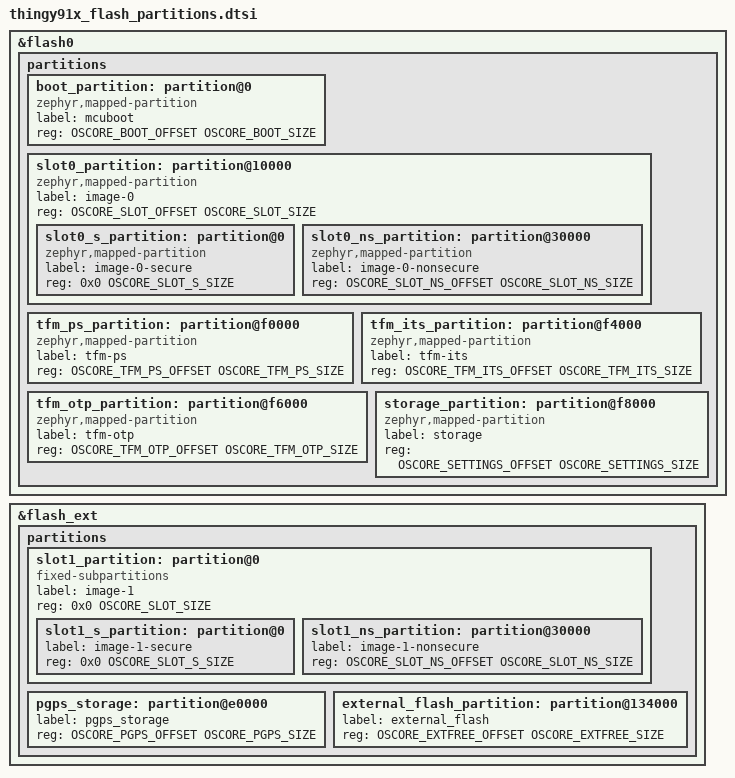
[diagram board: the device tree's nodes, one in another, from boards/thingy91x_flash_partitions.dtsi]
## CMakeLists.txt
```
# SPDX-License-Identifier: Apache-2.0
#
# Minimal OSCORE cloud sample for the nRF9151 DK. The oscore_cloud library is
# pulled in as a Zephyr module by the west manifest (west.yml), so it is built
# and linked automatically when CONFIG_OSCORE_CLOUD=y; this app only compiles
# its own main().

cmake_minimum_required(VERSION 3.20.0)

find_package(Zephyr REQUIRED HINTS $ENV{ZEPHYR_BASE})
project(oscore_nrf9151_app)

target_sources(app PRIVATE
	src/main.c
	src/network.c
)

target_sources_ifdef(CONFIG_LOCATION app PRIVATE
	src/location.c
	src/soak.c
)
```

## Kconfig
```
# SPDX-License-Identifier: Apache-2.0

mainmenu "OSCORE nRF9151 sample"

config APP_SAMPLE_INTERVAL_SECONDS
	int "Telemetry send interval (seconds)"
	default 600
	help
	  How long the main loop sleeps between telemetry check-ins once the
	  OSCORE cloud connection is established.

config APP_VERSION
	string "Reported firmware version string"
	default "1.0.0-oscore-sample"
	help
	  Value reported to the cloud in telemetry well-known key 2 (fw version).
	  Must be shorter than 24 bytes.

config APP_LINK_TIMEOUT_SECONDS
	int "LTE link-up wait timeout (seconds)"
	default 180
	help
	  How long to wait for the modem to register on the LTE network, both at
	  boot and after a link drop, before the recovery ladder escalates to the
	  next stage. The modem keeps searching in the background regardless.

config APP_MODEM_REINIT_AFTER_FAILURES
	int "Consecutive failures before reinitialising the modem"
	default 4
	help
	  Number of consecutive link-recovery attempts after which the recovery
	  ladder reaches its heaviest local step: a full modem-library
	  shutdown/reinit. Below this threshold it waits for auto re-registration
	  and, from the second failure, forces an LTE offline/normal re-attach.

config APP_AGNSS_SINGLE_SHOT_MAX_SV
	int "Single-shot A-GNSS satellite cap"
	depends on LOCATION && OSCORE_CLOUD_AGNSS
	default 9
	help
	  Number of satellites requested for a single-shot GNSS fix ("loc single"):
	  the server keeps only satellites visible now (>=10 deg elevation), picks
	  the strongest one per azimuth sector, and caps to this many for a small
	  assistance payload. 9 gives an extra strong SV of acquisition margin over
	  the 8-SV minimum while staying well under 1 kB with compact encoding. 0
	  leaves it uncapped.

source "Kconfig.zephyr"
```

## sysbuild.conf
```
# SPDX-License-Identifier: Apache-2.0
#
# Build MCUboot as the bootloader at flash 0x0. On the nRF9151 DK the board's
# flash layout reserves 0x0..0x10000 for the bootloader and links TF-M / the
# application AFTER it, so without MCUboot nothing valid sits at the reset
# address: the device boots into empty flash, faults, and produces no UART
# output. MCUboot boots from 0x0 and chainloads the TF-M secure image.
SB_CONFIG_BOOTLOADER_MCUBOOT=y

# Drop the immutable bootloader (b0) + updatable-MCUboot (s0/s1) chain that the
# Thingy:91 X enables by default for its factory partition layout. This app
# replaces that layout with the nRF9151 DK's -- a single first-stage MCUboot in
# boot_partition -- so that both boards have byte-identical internal flash; see
# boards/thingy91x_flash_partitions.dtsi. A second-stage MCUboot would also
# refuse to build here, since it requires zephyr,code-partition to be s0 or s1.
# No-op on the nRF9151 DK, which never enables secure boot.
SB_CONFIG_SECURE_BOOT_APPCORE=n
```

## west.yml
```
# SPDX-License-Identifier: Apache-2.0
#
# West T2 (star) manifest for the OSCORE nRF9151 sample.
#
# It imports sdk-nrf (which in turn imports Zephyr and all the usual modules),
# then adds two same-named / extra project entries that the top manifest wins
# over the imported ones:
#
#   * uoscore-uedhoc -> the joncloud-dev fork carrying the opaque PSA-key
#     changes required by the oscore_cloud library. A project with this name is
#     already pulled in by the sdk-nrf import; re-declaring it here at the top
#     level overrides that pin with our fork + branch.
#   * oscore_cloud   -> the reusable OSCORE cloud client module.
#
# To build against this manifest, clone this repo into an EMPTY workspace
# directory and run `west init -l . && west update` from there (this pulls the
# full NCS tree as siblings). For day-to-day iteration you can instead build
# inside an existing NCS workspace (see README).

manifest:
  version: "0.13"

  remotes:
    - name: ncs
      url-base: https://github.com/nrfconnect
    - name: joncloud-dev
      url-base: https://github.com/joncloud-dev

  projects:
    - name: sdk-nrf
      remote: ncs
      repo-path: sdk-nrf
      revision: 9f9725b23bc137e1e047c6a33773893b2c25ce0f  # NCS main (v3.4.99), 2026-11-03
      import: true

    # Overrides the uoscore-uedhoc pin imported via sdk-nrf with the fork that
    # provides opaque PSA master keys (branch oscore-opaque-psa-keys).
    - name: uoscore-uedhoc
      remote: joncloud-dev
      repo-path: uoscore-uedhoc
      revision: oscore-opaque-psa-keys
      path: modules/lib/uoscore-uedhoc

    # The reusable OSCORE cloud client library (standalone Zephyr module).
    - name: oscore_cloud
      remote: joncloud-dev
      repo-path: oscore_cloud
      revision: main
      path: modules/lib/oscore_cloud

  self:
    path: oscore_nrf9151_app
```

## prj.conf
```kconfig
# SPDX-License-Identifier: Apache-2.0
#
# Minimal configuration for the OSCORE cloud sample on nRF9151. Distilled from
# the Asset-Tracker-Template prj.conf: keeps only what the oscore_cloud library
# and its plain main()-loop session helper need (no zbus / SMF / storage / FOTA /
# location / diagnostics).

CONFIG_NCS_SAMPLES_DEFAULTS=y
# The diagnostics module (below) installs its own k_sys_fatal_error_handler to
# capture a crash snapshot before rebooting, so Zephyr's default reset-on-fatal
# handler must be disabled to keep a single definition of the symbol.
CONFIG_RESET_ON_FATAL_ERROR=n

# This sample drives OSCORE directly from the main thread, so main needs the
# headroom ATT gives its dedicated 14 KB cloud thread: with VLAs off, uoscore
# stages its plaintext[]/ciphertext[] buffers (OSCORE_MAX_PLAINTEXT_LEN=1536 +
# tag) plus the CoAP/telemetry frame on the caller's stack. 8 KB overflows on
# the first telemetry protect; 16 KB matches the known-good nrf9151_client.
CONFIG_MAIN_STACK_SIZE=16384
CONFIG_HEAP_MEM_POOL_SIZE=12288
CONFIG_HEAP_MEM_POOL_IGNORE_MIN=y
# Deferred AT monitors heap-copy notifications in the IPC ISR; 1 KiB default
# exhausts after a registration/PDN notification burst (e.g. post-flight).
CONFIG_AT_MONITOR_HEAP_SIZE=6144
CONFIG_EXTRA_EXCEPTION_INFO=y

# ---------------------------------------------------------------------------
# TF-M full profile: PSA crypto service required by uoscore-uedhoc (opaque
# master-secret key lives in the TF-M secure domain).
# ---------------------------------------------------------------------------
CONFIG_TFM_PROFILE_TYPE_NOT_SET=y
CONFIG_PSA_CRYPTO_DRIVER_CC3XX=y
CONFIG_TFM_PSA_FRAMEWORK_HAS_MM_IOVEC=y
CONFIG_PSA_WANT_ALG_CTR_DRBG=y

# Put TF-M's secure log on UART0 and share that instance with the non-secure
# app so both TF-M and the application console/shell come out on the DK's VCOM.
# Without this, TF-M defaults to a separate secure UART (uart1) and the console
# ends up on a port you are not watching -> "no UART output".
CONFIG_TFM_SECURE_UART0=y
CONFIG_TFM_SECURE_UART_SHARE_INSTANCE=y

# ---------------------------------------------------------------------------
# Networking: modem-offloaded sockets on the nRF91 (no native IP stack).
# ---------------------------------------------------------------------------
CONFIG_NETWORKING=y
CONFIG_NET_SOCKETS=y
CONFIG_NET_NATIVE=n
CONFIG_NET_IPV4=y

CONFIG_NRF_MODEM_LIB=y
CONFIG_LTE_LINK_CONTROL=y
CONFIG_LTE_NETWORK_MODE_LTE_M_NBIOT_GPS=y

# LTE Link Control submodules used by the network module (src/network.c):
#  - PDN: the network module treats the default-PDN activate/deactivate events
#    as the authoritative link-up/down signal (an IP bearer is actually usable),
#    rather than raw registration status.
#  - MODEM_EVENTS: surfaces attach reset-loop and light/full search-done
#    notifications (enabled automatically by the lte_lc CFUN hook).
#  - PSM/eDRX: request power-saving parameters and forward the negotiated values
#    to the application as network events.
CONFIG_LTE_LC_PDN_MODULE=y
CONFIG_LTE_LC_MODEM_EVENTS_MODULE=y
CONFIG_LTE_LC_PSM_MODULE=y
CONFIG_LTE_PSM_REQ=y
CONFIG_LTE_LC_EDRX_MODULE=y
CONFIG_LTE_EDRX_REQ=y
CONFIG_LTE_PSM_REQ_RPTAU_SECONDS=7200
CONFIG_LTE_PSM_REQ_RAT_SECONDS=6
# Modem info: feeds the diagnostics vitals heartbeat (RSRP/SNR/temp/band, tx/rx
# airtime) and the one-shot device-info report (modem firmware, IMEI, ICCID).
CONFIG_MODEM_INFO=y
CONFIG_MODEM_INFO_ADD_NETWORK=y

# Wall-clock time (optional telemetry timestamp; the server also stamps).
CONFIG_DATE_TIME=y

# ---------------------------------------------------------------------------
# GNSS location + A-GNSS assistance over OSCORE.
#
# The Location library runs a GNSS-only search (src/location.c). A-GNSS
# assistance is fetched from the OSCORE cloud, not nRF Cloud. The Location
# library only *exposes* the external assistance-request event
# (LOCATION_EVT_GNSS_ASSISTANCE_REQUEST + event_data.agnss_request) when
# CONFIG_NRF_CLOUD_AGNSS is set, which in turn lives under CONFIG_NRF_CLOUD.
# We therefore enable the nRF Cloud *library* for the request plumbing only:
# with no transport (no NRF_CLOUD_MQTT/COAP) and CONFIG_LOCATION_SERVICE_EXTERNAL
# =y, no connection is made — the library hands the request to our handler,
# which fetches over OSCORE and injects via nrf_modem_gnss_agnss_write().
CONFIG_LOCATION=y
CONFIG_LOCATION_DATA_DETAILS=y
CONFIG_LOCATION_METHOD_GNSS=y
CONFIG_LOCATION_SERVICE_EXTERNAL=y
CONFIG_NRF_CLOUD=y
CONFIG_NRF_CLOUD_AGNSS=y
CONFIG_LOCATION_REQUEST_DEFAULT_GNSS_TIMEOUT=120000
CONFIG_LOCATION_REQUEST_DEFAULT_TIMEOUT=120000

# The Location library always builds scan_cellular.c, which requires an AT
# monitor heap large enough to hold neighbor-cell measurement notifications.
CONFIG_AT_MONITOR_HEAP_SIZE=1024

# oscore_cloud A-GNSS client (POST /a, Block2 CBOR -> nrf_modem_gnss_agnss_write).
CONFIG_OSCORE_CLOUD_AGNSS=y

# oscore_cloud predicted-GNSS (P-GPS) client (POST /p, Block2 CBOR -> flash
# window ring -> nrf_modem_gnss_agnss_write). Exposes the `pgps fetch` /
# `pgps fix` / `pgps store` shell commands.
CONFIG_OSCORE_CLOUD_PGPS=y
# Keep the downloaded windows in the pgps_storage partition on external flash
# (boards/nrf9151dk_nrf9151_ns.overlay), one 4 KiB slot per 4 h window. 84 slots
# is the full 14-day horizon the /p contract defines, and it survives reboots so
# the device can fix from stored predictions while completely offline -- which is
# what the `soak` bench test measures.
CONFIG_OSCORE_CLOUD_PGPS_STORE=y
CONFIG_OSCORE_CLOUD_PGPS_STORE_SLOTS=84
# Windows per POST /p. A whole horizon cannot arrive in one response (84 windows
# is ~97 kB against a 12 KiB accumulation buffer), so a long fetch is split into
# this many windows per request, one request per main-loop iteration.
CONFIG_OSCORE_CLOUD_PGPS_FETCH_BATCH=6

# ---------------------------------------------------------------------------
# OSCORE cloud transport.
# ---------------------------------------------------------------------------
CONFIG_COAP=y
CONFIG_UOSCORE=y
CONFIG_OSCORE_USE_EDHOC=n
CONFIG_ZCBOR=y
CONFIG_ZCBOR_CANONICAL=y
CONFIG_MBEDTLS=y
CONFIG_PSA_WANT_ALG_HMAC=y
CONFIG_PSA_WANT_ALG_SHA_256=y
CONFIG_PSA_WANT_KEY_TYPE_HMAC=y
CONFIG_PSA_WANT_ALG_CCM=y
CONFIG_PSA_WANT_KEY_TYPE_AES=y
#CONFIG_OSCORE_SERVER_IP="23.88.115.159"
CONFIG_OSCORE_SERVER_IP="34.148.113.218"

CONFIG_COAP_MAX_RETRANSMIT=3
CONFIG_COAP_INIT_ACK_TIMEOUT_MS=5000

# ---------------------------------------------------------------------------
# oscore_cloud library: enable the client and the framework-free session helper
# (connect / backoff / send_telemetry).
# ---------------------------------------------------------------------------
CONFIG_OSCORE_CLOUD=y
CONFIG_OSCORE_CLOUD_SESSION=y

# OSCORE FOTA of the application image (GET/POST /f + Block2 /f/i). The session
# helper drives the download when a telemetry response flags a pending job;
# main.c calls fota_client_boot_check() at boot to confirm the swapped image and
# report the result. The image streams into the MCUboot secondary slot on
# external flash; progress is persisted so an interrupted download resumes.
CONFIG_OSCORE_CLOUD_FOTA=y
CONFIG_DFU_TARGET=y
CONFIG_DFU_TARGET_MCUBOOT=y
CONFIG_DFU_TARGET_STREAM=y
CONFIG_DFU_TARGET_STREAM_SAVE_PROGRESS=y
CONFIG_STREAM_FLASH=y
CONFIG_IMG_MANAGER=y
CONFIG_MCUBOOT_IMG_MANAGER=y
CONFIG_IMG_ERASE_PROGRESSIVELY=y
CONFIG_DFU_TARGET_LOG_LEVEL_INF=y

# The network module (src/network.c) tracks the LTE link state with a kernel
# event object (k_event) so the main connect/send loop can block on, and react
# to, default-PDN activation/deactivation.
CONFIG_EVENTS=y

# ---------------------------------------------------------------------------
# Device observability (Memfault-style): reboot reasons (key 20), a health
# vitals heartbeat (key 21), minimal crash reports (key 22) and static device
# info (key 23), all folded into the ordinary telemetry uplink. The session
# helper attaches them automatically (OSCORE_CLOUD_DIAG_AUTO_ATTACH, default y);
# main.c only calls oscore_cloud_diag_init() once at boot. See OBSERVABILITY.md.
# ---------------------------------------------------------------------------
CONFIG_OSCORE_CLOUD_DIAG=y
CONFIG_OSCORE_CLOUD_DIAG_VITALS=y
CONFIG_OSCORE_CLOUD_DIAG_CRASH=y
CONFIG_OSCORE_CLOUD_DIAG_BREADCRUMBS=y
CONFIG_OSCORE_CLOUD_DIAG_BREADCRUMB_SIZE=1024
CONFIG_OSCORE_CLOUD_DIAG_BUILD_ID=y
CONFIG_OSCORE_CLOUD_DIAG_DEVICE_INFO=y
# Attach the vitals heartbeat on every telemetry send (raise to post fleet
# vitals at a lower cadence than telemetry while sharing the same packet).
CONFIG_OSCORE_CLOUD_DIAG_VITALS_INTERVAL=1

# Reset cause + planned reboot (selected by OSCORE_CLOUD_DIAG, listed for clarity).
CONFIG_HWINFO=y
CONFIG_REBOOT=y

# Vitals sources: heap/stack headroom and CPU busy percent. Modem signal quality
# and airtime vitals reuse CONFIG_MODEM_INFO / CONFIG_LTE_LINK_CONTROL above.
CONFIG_SYS_HEAP_RUNTIME_STATS=y
CONFIG_THREAD_MONITOR=y
CONFIG_THREAD_STACK_INFO=y
CONFIG_THREAD_RUNTIME_STATS=y

# Full coredump is off. It was originally disabled because the image did not fit
# the 256 KB application slot alongside the Location + nRF Cloud (A-GNSS request
# plumbing) + cJSON libraries. That constraint is gone -- moving the MCUboot
# secondary slot to external flash gave the application 704 KB (see
# boards/oscore_flash_layout.h) -- so this can be re-enabled now; it also needs a
# coredump_partition nodelabel, which neither board layout defines yet. The
# minimal inline crash report (diag key 22) covers the crash case meanwhile.
CONFIG_DEBUG_COREDUMP=n

# ---------------------------------------------------------------------------
# Persistent storage: the OSCORE Sender Sequence Number (replay counter) is
# saved to NVS so the server does not reject requests as replays after reboot.
# Uses the board's default `storage_partition` on internal flash.
# ---------------------------------------------------------------------------
CONFIG_FLASH=y
CONFIG_FLASH_MAP=y
CONFIG_NVS=y
CONFIG_SETTINGS=y
CONFIG_SETTINGS_NVS=y

# ---------------------------------------------------------------------------
# Shell: one-time bench provisioning via `oscore provision <secret> <salt>
# <sender_id> <recipient_id>` (registered by the oscore_cloud library).
# ---------------------------------------------------------------------------
CONFIG_UART_INTERRUPT_DRIVEN=y
CONFIG_SHELL=y
CONFIG_SHELL_STACK_SIZE=2560
CONFIG_SHELL_CMD_BUFF_SIZE=2048

# Floating point for telemetry values.
CONFIG_PICOLIBC=y
CONFIG_FPU=y

# Logging.
CONFIG_LOG=y
CONFIG_LOG_MODE_DEFERRED=y
CONFIG_LOG_BUFFER_SIZE=2048
# Needed to log the negotiated eDRX/PTW values (floats) from the network module.
CONFIG_CBPRINTF_FP_SUPPORT=y
# Keep the OSCORE cloud library at INF (default): DBG-level strings are rodata
# that no longer fits once the GNSS/location libraries are linked in.
CONFIG_LOCATION_LOG_LEVEL_DBG=y
```

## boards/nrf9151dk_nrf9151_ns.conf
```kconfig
# SPDX-License-Identifier: Apache-2.0
#
# Enable the DK's external SPI NOR flash (GD25WB256, 32 MiB on spi3 CS1). The
# node ships `status = "disabled"` in the board devicetree; the overlay enables
# it and carves out the pgps_storage partition that holds the predicted-GNSS
# window ring. There is no QSPI on the nRF9151, so this is a plain SPI NOR
# driver over SPIM.
CONFIG_SPI=y
CONFIG_SPI_NOR=y
CONFIG_SPI_NOR_SFDP_DEVICETREE=y
CONFIG_SPI_NOR_FLASH_LAYOUT_PAGE_SIZE=4096
```

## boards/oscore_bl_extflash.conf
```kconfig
# SPDX-License-Identifier: Apache-2.0
#
# MCUboot's secondary slot (slot1_partition) is on external SPI NOR on both
# boards, so the bootloader needs the driver to read and swap it. Keeping slot1
# internal instead would cost the application 448 KB of the 1 MiB part -- see
# boards/oscore_flash_layout.h.
CONFIG_SPI=y
CONFIG_SPI_NOR=y
CONFIG_SPI_NOR_SFDP_DEVICETREE=y
CONFIG_SPI_NOR_FLASH_LAYOUT_PAGE_SIZE=4096
```

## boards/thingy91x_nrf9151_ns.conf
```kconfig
# SPDX-License-Identifier: Apache-2.0
#
# The predicted-GNSS window ring lives in the pgps_storage partition on the
# on-board external SPI NOR flash (GD25LE255E, 32 MiB on spi3 CS0), so the
# application needs the SPI NOR driver. There is no QSPI on the nRF9151.
#
# Note that settings/NVS is on INTERNAL flash on this target (see
# thingy91x_flash_partitions.dtsi), so CONFIG_SPI_NRFX_RAM_BUFFER_SIZE does not
# need raising: nothing writes rodata-resident buffers over SPIM.
CONFIG_SPI=y
CONFIG_SPI_NOR=y
CONFIG_SPI_NOR_SFDP_DEVICETREE=y
CONFIG_SPI_NOR_FLASH_LAYOUT_PAGE_SIZE=4096

# This app replaces the factory b0 + s0/s1 chain with a single first-stage
# MCUboot (SB_CONFIG_SECURE_BOOT_APPCORE=n in sysbuild.conf), so the immutable
# bootloader is not present and the application must not build against its
# interface. The board's Kconfig.defconfig turns this on by default.
CONFIG_SECURE_BOOT=n
```

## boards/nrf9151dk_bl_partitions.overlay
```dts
/*
 * SPDX-License-Identifier: Apache-2.0
 *
 * Flash layout for the nrf9151dk MCUboot image, applied by sysbuild.cmake.
 *
 * MCUboot must see exactly the same partition bounds as the application: this
 * app grows slot0 and moves slot1 to external flash, and a bootloader that
 * disagreed would write its image trailer outside the slot. Board .overlay files
 * reach only the application image, hence this.
 */

#include "nrf9151dk_flash_partitions.dtsi"

/*
 * Link MCUboot into boot_partition.
 *
 * MCUboot's own boot/zephyr/app.overlay is what normally chooses this, but it is
 * only applied when Zephyr does not find a board-specific overlay in
 * boot/zephyr/boards/. MCUboot ships one for the Thingy:91 X
 * (thingy91x_nrf9151.overlay, which just raises the UART baud), so on that board
 * app.overlay is skipped and zephyr,code-partition stays &slot0_partition from
 * the board devicetree -- linking MCUboot on top of the application image and
 * leaving nothing at the reset vector. Set it explicitly here, for both boards,
 * so the layout does not depend on which overlays upstream happens to ship.
 */
/ {
	chosen {
		zephyr,code-partition = &boot_partition;
	};
};
```

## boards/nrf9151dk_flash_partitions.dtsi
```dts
/*
 * SPDX-License-Identifier: Apache-2.0
 *
 * nRF9151 DK flash layout. Shared by the application image and by MCUboot (see
 * sysbuild.cmake); both must agree, or MCUboot writes its image trailer outside
 * the slot. Addresses and sizes come from oscore_flash_layout.h, which documents
 * the layout and why it is what it is.
 *
 * The board's stock devicetree (zephyr/dts/vendor/nordic/nrf91xx_partition.dtsi)
 * already provides boot_partition, the TF-M storage areas and the settings
 * partition at the right addresses, so only the two image slots are rebuilt:
 * slot0 grows into the 448 KB that slot1 used to occupy, and slot1 moves to the
 * external SPI NOR chip.
 */

#include "oscore_flash_layout.h"

/delete-node/ &slot0_partition;
/delete-node/ &slot1_partition;

&flash0 {
	partitions {
		slot0_partition: partition@10000 {
			compatible = "zephyr,mapped-partition";
			label = "image-0";
			reg = <OSCORE_SLOT_OFFSET OSCORE_SLOT_SIZE>;
			ranges = <0x0 OSCORE_SLOT_OFFSET OSCORE_SLOT_SIZE>;
			#address-cells = <1>;
			#size-cells = <1>;

			slot0_s_partition: partition@0 {
				compatible = "zephyr,mapped-partition";
				label = "image-0-secure";
				reg = <0x0 OSCORE_SLOT_S_SIZE>;
			};

			slot0_ns_partition: partition@30000 {
				compatible = "zephyr,mapped-partition";
				label = "image-0-nonsecure";
				reg = <OSCORE_SLOT_NS_OFFSET OSCORE_SLOT_NS_SIZE>;
			};
		};
	};
};

/* The DK's 32 MiB GD25WB256 sits on spi3 CS1 and ships disabled; spi3 itself is
 * already enabled by the board. Enabled here rather than in the board .overlay
 * so MCUboot, which now reaches slot1 through it, gets it too. */
&gd25wb256 {
	status = "okay";

	partitions {
		compatible = "fixed-partitions";
		#address-cells = <1>;
		#size-cells = <1>;

		slot1_partition: partition@0 {
			compatible = "fixed-subpartitions";
			label = "image-1";
			/* MUST equal slot0_partition: MCUboot's swap refuses to run
			 * when the primary and secondary slots differ in size. */
			reg = <0x0 OSCORE_SLOT_SIZE>;
			ranges = <0x0 0x0 OSCORE_SLOT_SIZE>;
			#address-cells = <1>;
			#size-cells = <1>;

			slot1_s_partition: partition@0 {
				label = "image-1-secure";
				reg = <0x0 OSCORE_SLOT_S_SIZE>;
			};

			slot1_ns_partition: partition@30000 {
				label = "image-1-nonsecure";
				reg = <OSCORE_SLOT_NS_OFFSET OSCORE_SLOT_NS_SIZE>;
			};
		};

		pgps_storage: partition@e0000 {
			label = "pgps_storage";
			reg = <OSCORE_PGPS_OFFSET OSCORE_PGPS_SIZE>;
		};

		external_flash_partition: partition@134000 {
			label = "external_flash";
			reg = <OSCORE_EXTFREE_OFFSET OSCORE_EXTFREE_SIZE>;
		};
	};
};
```

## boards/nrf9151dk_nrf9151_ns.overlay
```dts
/*
 * SPDX-License-Identifier: Apache-2.0
 *
 * nRF9151 DK application image.
 *
 * The flash layout is shared with the MCUboot image (see sysbuild.cmake and
 * nrf9151dk_flash_partitions.dtsi). Two things it changes from the board default,
 * both explained in oscore_flash_layout.h: the secure/non-secure boundary inside
 * slot0 moves down so TF-M's full profile fits, and slot1 moves to the external
 * SPI NOR chip so the application gets 704 KB instead of 256 KB.
 *
 * The SRAM split is the board's stock 88 KB secure / 168 KB non-secure, which
 * this app already runs with.
 */

#include "nrf9151dk_flash_partitions.dtsi"
```

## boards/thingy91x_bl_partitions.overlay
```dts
/*
 * SPDX-License-Identifier: Apache-2.0
 *
 * Flash layout for the thingy91x MCUboot image, applied by sysbuild.cmake.
 *
 * MCUboot must see exactly the same partition bounds as the application: this
 * app grows slot0 and moves slot1 to external flash, and a bootloader that
 * disagreed would write its image trailer outside the slot. Board .overlay files
 * reach only the application image, hence this.
 */

#include "thingy91x_flash_partitions.dtsi"

/*
 * Link MCUboot into boot_partition.
 *
 * MCUboot's own boot/zephyr/app.overlay is what normally chooses this, but it is
 * only applied when Zephyr does not find a board-specific overlay in
 * boot/zephyr/boards/. MCUboot ships one for the Thingy:91 X
 * (thingy91x_nrf9151.overlay, which just raises the UART baud), so on that board
 * app.overlay is skipped and zephyr,code-partition stays &slot0_partition from
 * the board devicetree -- linking MCUboot on top of the application image and
 * leaving nothing at the reset vector. Set it explicitly here, for both boards,
 * so the layout does not depend on which overlays upstream happens to ship.
 */
/ {
	chosen {
		zephyr,code-partition = &boot_partition;
	};
};
```

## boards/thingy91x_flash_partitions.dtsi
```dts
/*
 * SPDX-License-Identifier: Apache-2.0
 *
 * Thingy:91 X flash layout -- the same layout the nRF9151 DK uses. Shared by the
 * application image and by MCUboot (see sysbuild.cmake). Addresses and sizes
 * come from oscore_flash_layout.h, which documents the layout and the reasoning.
 *
 * The Thingy:91 X ships the factory b0 + updatable-MCUboot (s0/s1) chain and
 * spends its entire 1 MiB on it, with no TF-M storage partitions at all, so the
 * whole internal layout is rebuilt here. Two things made the factory layout
 * unusable for this app:
 *
 *   1. NCS derives TF-M's PS/ITS/OTP areas from the tfm_ps_partition /
 *      tfm_its_partition / tfm_otp_partition nodelabels (see
 *      nrf/modules/trusted-firmware-m/tfm_boards/partition/flash_layout.h). With
 *      none of them present a full-profile TF-M build -- which this app needs,
 *      since uoscore-uedhoc keeps the OSCORE master secret as an opaque PSA key
 *      and the provisioned key is persistent, living in Internal Trusted Storage
 *      -- fails with "TFM_OTP_NV_COUNTERS_AREA_ADDR must be defined in
 *      flash_layout.h".
 *   2. MCUboot built as a second stage (under b0, running from s0/s1) requires
 *      zephyr,code-partition to be s0_partition or s1_partition, while its own
 *      app.overlay chooses &boot_partition, which the factory layout lacks.
 *
 * SB_CONFIG_SECURE_BOOT_APPCORE=n in sysbuild.conf drops b0 to match.
 *
 * fmfu_storage_partition is reclaimed: the board declares it but nothing chooses
 * it, and this app does not do full-modem-firmware updates.
 *
 * NOT interchangeable with Thingy:91 X factory firmware over USB DFU -- both the
 * bootloader chain and the slot bounds change. Flash the whole image.
 */

#include "oscore_flash_layout.h"

/delete-node/ &b0_partition;
/delete-node/ &s0_partition;
/delete-node/ &s1_partition;
/delete-node/ &slot0_partition;
/delete-node/ &slot1_partition;
/delete-node/ &fmfu_storage_partition;
/delete-node/ &storage_partition;
/delete-node/ &external_flash_partition;

&flash0 {
	partitions {
		boot_partition: partition@0 {
			compatible = "zephyr,mapped-partition";
			label = "mcuboot";
			reg = <OSCORE_BOOT_OFFSET OSCORE_BOOT_SIZE>;
		};

		slot0_partition: partition@10000 {
			compatible = "zephyr,mapped-partition";
			label = "image-0";
			reg = <OSCORE_SLOT_OFFSET OSCORE_SLOT_SIZE>;
			ranges = <0x0 OSCORE_SLOT_OFFSET OSCORE_SLOT_SIZE>;
			#address-cells = <1>;
			#size-cells = <1>;

			slot0_s_partition: partition@0 {
				compatible = "zephyr,mapped-partition";
				label = "image-0-secure";
				reg = <0x0 OSCORE_SLOT_S_SIZE>;
			};

			slot0_ns_partition: partition@30000 {
				compatible = "zephyr,mapped-partition";
				label = "image-0-nonsecure";
				reg = <OSCORE_SLOT_NS_OFFSET OSCORE_SLOT_NS_SIZE>;
			};
		};

		tfm_ps_partition: partition@f0000 {
			compatible = "zephyr,mapped-partition";
			label = "tfm-ps";
			reg = <OSCORE_TFM_PS_OFFSET OSCORE_TFM_PS_SIZE>;
		};

		tfm_its_partition: partition@f4000 {
			compatible = "zephyr,mapped-partition";
			label = "tfm-its";
			reg = <OSCORE_TFM_ITS_OFFSET OSCORE_TFM_ITS_SIZE>;
		};

		tfm_otp_partition: partition@f6000 {
			compatible = "zephyr,mapped-partition";
			label = "tfm-otp";
			reg = <OSCORE_TFM_OTP_OFFSET OSCORE_TFM_OTP_SIZE>;
		};

		storage_partition: partition@f8000 {
			compatible = "zephyr,mapped-partition";
			label = "storage";
			reg = <OSCORE_SETTINGS_OFFSET OSCORE_SETTINGS_SIZE>;
		};
	};
};

/* The 32 MiB GD25LE255E sits on spi3 CS0 and ships disabled; spi3 itself is
 * already enabled for the nRF9151 target. Enabled here rather than in the board
 * .overlay so MCUboot, which reaches slot1 through it, gets it too. */
&flash_ext {
	status = "okay";

	partitions {
		slot1_partition: partition@0 {
			compatible = "fixed-subpartitions";
			label = "image-1";
			/* MUST equal slot0_partition: MCUboot's swap refuses to run
			 * when the primary and secondary slots differ in size. */
			reg = <0x0 OSCORE_SLOT_SIZE>;
			ranges = <0x0 0x0 OSCORE_SLOT_SIZE>;
			#address-cells = <1>;
			#size-cells = <1>;

			slot1_s_partition: partition@0 {
				label = "image-1-secure";
				reg = <0x0 OSCORE_SLOT_S_SIZE>;
			};

			slot1_ns_partition: partition@30000 {
				label = "image-1-nonsecure";
				reg = <OSCORE_SLOT_NS_OFFSET OSCORE_SLOT_NS_SIZE>;
			};
		};

		pgps_storage: partition@e0000 {
			label = "pgps_storage";
			reg = <OSCORE_PGPS_OFFSET OSCORE_PGPS_SIZE>;
		};

		external_flash_partition: partition@134000 {
			label = "external_flash";
			reg = <OSCORE_EXTFREE_OFFSET OSCORE_EXTFREE_SIZE>;
		};
	};
};
```

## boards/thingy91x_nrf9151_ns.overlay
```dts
/*
 * SPDX-License-Identifier: Apache-2.0
 *
 * Thingy:91 X application image.
 *
 * The flash layout is shared with the MCUboot image (see sysbuild.cmake and the
 * header of thingy91x_flash_partitions.dtsi, which explains why the factory
 * layout cannot be used). Only the SRAM split below is application-only:
 * MCUboot runs without TF-M and keeps the board's.
 */

#include "thingy91x_flash_partitions.dtsi"

/* ------------------------------------------------------------------------- *
 * SRAM: the board splits 256 KB as 32 KB secure / 224 KB non-secure, sized for
 * TF-M's minimal profile. The full profile does not fit in 32 KB.
 *
 *   sram0_s   0x20000000..0x20016000  ( 88 KB)
 *   sram0_ns  0x20016000..0x20040000  (168 KB)
 *     modem shared area              (17768 B, board values kept verbatim)
 *     sram0_ns_app                   (~150 KB)
 *
 * 88 KB secure is the stock Zephyr nRF91 split this app already runs with on the
 * DK, so it introduces no new unknown, and the non-secure app still gets ~150 KB
 * against the DK's 128 KB. The modem IPC regions are reproduced exactly as the
 * board sizes them; shrinking them would change modem throughput.
 * ------------------------------------------------------------------------- */

/delete-node/ &sram0_s;
/delete-node/ &sram0_ns;

&sram0 {
	sram0_s: sram@0 {
		reg = <0x0 0x16000>;
	};

	sram0_ns: sram@16000 {
		reg = <0x16000 0x2a000>;
		#address-cells = <1>;
		#size-cells = <1>;
		ranges = <0x0 0x16000 0x2a000>;

		/* Must be in the first 128 kB of RAM. */
		sram0_ns_modem: sram0_ns@0 {
			reg = <0x0 0x4568>;
			#address-cells = <1>;
			#size-cells = <1>;
			ranges = <0x0 0x0 0x4568>;

			cpuapp_cpucell_ipc_shm_ctrl: sram0_ns_modem@0 {
				reg = <0x0 0x4e8>;
			};

			cpuapp_cpucell_ipc_shm_heap: sram0_ns_modem@4e8 {
				reg = <0x4e8 0x2080>;
			};

			cpucell_cpuapp_ipc_shm_heap: sram0_ns_modem@2568 {
				reg = <0x2568 0x2000>;
			};
		};

		sram0_ns_app: sram0_ns@4568 {
			reg = <0x4568 0x25a98>;
		};
	};
};
```

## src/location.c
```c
/*
 * SPDX-License-Identifier: Apache-2.0
 *
 * Minimal GNSS location feature. See location.h.
 */

#include <zephyr/kernel.h>
#include <zephyr/logging/log.h>

#include <modem/location.h>
#include <nrf_modem_gnss.h>
#include <date_time.h>

#include "location.h"

LOG_MODULE_REGISTER(app_location, LOG_LEVEL_INF);

/* Shared state between the Location library workqueue (writer) and main()
 * (reader/consumer). A single mutex keeps the frame copy + flags consistent. */
static K_MUTEX_DEFINE(loc_lock);

static bool search_active;
static enum app_assist current_assist;
static bool current_all;     /* fetch the full constellation (skip server pruning) */

static bool agnss_pending;
static bool agnss_fetched;   /* fetched/injected at least once for the current search */
static struct nrf_modem_gnss_agnss_data_frame agnss_frame;

static bool fix_ready;
static struct app_fix pending_fix;
static uint32_t fix_count;

static bool have_last_coords;
static double last_lat, last_lon;
static uint32_t last_unc_m;

static void search_reset(enum app_assist mode, bool all)
{
	k_mutex_lock(&loc_lock, K_FOREVER);
	search_active = true;
	current_assist = mode;
	current_all = all;
	agnss_pending = false;
	agnss_fetched = false;
	k_mutex_unlock(&loc_lock);
}

static void search_end(void)
{
	k_mutex_lock(&loc_lock, K_FOREVER);
	search_active = false;
	agnss_pending = false;
	k_mutex_unlock(&loc_lock);
}

static void store_fix(const struct location_data *loc)
{
	struct app_fix f = {
		.lat = loc->latitude,
		.lon = loc->longitude,
		.accuracy_m = loc->accuracy,
	};
	int64_t now_ms;

#if defined(CONFIG_LOCATION_DATA_DETAILS)
	f.ttff_ms = (uint32_t)loc->details.gnss.pvt_data.execution_time;
	if (loc->details.gnss.pvt_data.flags & NRF_MODEM_GNSS_PVT_FLAG_FIX_VALID) {
		f.alt_m = loc->details.gnss.pvt_data.altitude;
		f.has_alt = true;
	}
#endif
	if (date_time_now(&now_ms) == 0) {
		f.timestamp = now_ms / 1000;
	}

	k_mutex_lock(&loc_lock, K_FOREVER);
	pending_fix = f;
	fix_ready = true;
	fix_count++;
	have_last_coords = true;
	last_lat = f.lat;
	last_lon = f.lon;
	/* A fresh fix is precise; a small non-zero uncertainty lets the server
	 * prune hard while leaving the elevation mask a little margin. */
	last_unc_m = (f.accuracy_m > 1.0) ? (uint32_t)f.accuracy_m : 50;
	k_mutex_unlock(&loc_lock);
}

static void location_event_handler(const struct location_event_data *event_data)
{
	switch (event_data->id) {
	case LOCATION_EVT_STARTED:
		LOG_DBG("Location search started");
		break;

	case LOCATION_EVT_LOCATION:
		LOG_INF("Got fix: %.06f, %.06f (acc %.1f m)",
			(double)event_data->location.latitude,
			(double)event_data->location.longitude,
			(double)event_data->location.accuracy);
		store_fix(&event_data->location);
		search_end();
		break;

#if defined(CONFIG_NRF_CLOUD_AGNSS)
	case LOCATION_EVT_GNSS_ASSISTANCE_REQUEST:
		k_mutex_lock(&loc_lock, K_FOREVER);
		if (agnss_fetched) {
			/* Already served a (partial) set this search; the modem will
			 * fix with what it has. Ignore to avoid a fetch loop. */
			LOG_DBG("A-GNSS re-request ignored (already fetched this search)");
		} else {
			agnss_frame = event_data->agnss_request;
			agnss_pending = true;
			LOG_DBG("A-GNSS assistance request pending");
		}
		k_mutex_unlock(&loc_lock);
		break;
#endif

	case LOCATION_EVT_TIMEOUT:
		LOG_WRN("Location search timed out");
		search_end();
		break;

	case LOCATION_EVT_ERROR:
		LOG_WRN("Location search failed");
		search_end();
		break;

	case LOCATION_EVT_RESULT_UNKNOWN:
		LOG_DBG("Location result unknown");
		search_end();
		break;

	default:
		LOG_DBG("Location event %d", event_data->id);
		break;
	}
}

int app_location_init(void)
{
	int err = location_init(location_event_handler);

	if (err) {
		LOG_ERR("location_init failed: %d", err);
		return err;
	}
	LOG_INF("Location library initialised");
	return 0;
}

const char *app_assist_name(enum app_assist mode)
{
	switch (mode) {
	case APP_ASSIST_AGNSS_SINGLE:
		return "A-GNSS single-shot";
	case APP_ASSIST_AGNSS_WINDOW:
		return "A-GNSS 2h window";
	case APP_ASSIST_PGPS:
		return "P-GPS stored window";
	case APP_ASSIST_NONE:
		return "unassisted";
	default:
		return "?";
	}
}

int app_location_request_assist(enum app_assist mode, bool all)
{
	struct location_config config;
	enum location_method methods[] = { LOCATION_METHOD_GNSS };
	int err;

	location_config_defaults_set(&config, 1, methods);
	/* Bound the GNSS search so it cannot hang waiting for a "complete"
	 * assistance set that the pruned response will never provide. */
	config.methods[0].gnss.timeout = 120 * MSEC_PER_SEC;
	/* On the first fix after boot the modem is still active on LTE (attach,
	 * telemetry, the A-GNSS fetch itself), so GNSS gets only short RF windows
	 * between LTE idle-mode operations and can take ~60 s even with valid
	 * assistance. Priority mode lets GNSS pre-empt LTE if five consecutive PVTs
	 * are blocked; the library auto-disables it after the first fix or 40 s, so
	 * it only affects the slow first acquisition. */
	config.methods[0].gnss.priority_mode = true;

	search_reset(mode, all);

	err = location_request(&config);
	if (err) {
		LOG_ERR("location_request (%s) failed: %d", app_assist_name(mode), err);
		search_end();
		return err;
	}
	LOG_INF("GNSS search requested (%s%s)", app_assist_name(mode), all ? ", all SVs" : "");
	return 0;
}

int app_location_request(bool single_shot, bool all)
{
	return app_location_request_assist(single_shot ? APP_ASSIST_AGNSS_SINGLE
						       : APP_ASSIST_AGNSS_WINDOW,
					   all);
}

int app_location_request_pgps(void)
{
	return app_location_request_assist(APP_ASSIST_PGPS, false);
}

bool app_location_search_active(void)
{
	bool active;

	k_mutex_lock(&loc_lock, K_FOREVER);
	active = search_active;
	k_mutex_unlock(&loc_lock);
	return active;
}

bool app_location_agnss_pending(struct nrf_modem_gnss_agnss_data_frame *frame,
				bool *single_shot, bool *all)
{
	bool pending;

	k_mutex_lock(&loc_lock, K_FOREVER);
	/* Only the two A-GNSS modes are served over the network. In P-GPS mode the
	 * assistance-need is serviced by injecting a stored predicted window
	 * (app_location_pgps_pending), and APP_ASSIST_NONE serves nothing at all,
	 * so the modem fixes on sky-decoded data only. */
	pending = agnss_pending && (current_assist == APP_ASSIST_AGNSS_SINGLE ||
				    current_assist == APP_ASSIST_AGNSS_WINDOW);
	if (pending) {
		if (frame) {
			*frame = agnss_frame;
		}
		if (single_shot) {
			*single_shot = (current_assist == APP_ASSIST_AGNSS_SINGLE);
		}
		if (all) {
			*all = current_all;
		}
		agnss_pending = false;
	}
	k_mutex_unlock(&loc_lock);
	return pending;
}

bool app_location_pgps_pending(struct nrf_modem_gnss_agnss_data_frame *frame)
{
	bool pending;

	k_mutex_lock(&loc_lock, K_FOREVER);
	pending = agnss_pending && current_assist == APP_ASSIST_PGPS;
	if (pending) {
		if (frame) {
			*frame = agnss_frame;
		}
		agnss_pending = false;
	}
	k_mutex_unlock(&loc_lock);
	return pending;
}

void app_location_agnss_mark_fetched(void)
{
	k_mutex_lock(&loc_lock, K_FOREVER);
	agnss_fetched = true;
	k_mutex_unlock(&loc_lock);
}

bool app_location_get_fix(struct app_fix *fix)
{
	bool ready;

	k_mutex_lock(&loc_lock, K_FOREVER);
	ready = fix_ready;
	if (ready) {
		if (fix) {
			*fix = pending_fix;
		}
		fix_ready = false;
	}
	k_mutex_unlock(&loc_lock);
	return ready;
}

uint32_t app_location_fix_count(void)
{
	uint32_t n;

	k_mutex_lock(&loc_lock, K_FOREVER);
	n = fix_count;
	k_mutex_unlock(&loc_lock);
	return n;
}

bool app_location_last_coords(double *lat, double *lon, uint32_t *unc_m)
{
	bool have;

	k_mutex_lock(&loc_lock, K_FOREVER);
	have = have_last_coords;
	if (have) {
		if (lat) {
			*lat = last_lat;
		}
		if (lon) {
			*lon = last_lon;
		}
		if (unc_m) {
			*unc_m = last_unc_m;
		}
	}
	k_mutex_unlock(&loc_lock);
	return have;
}

void app_location_set_last_coords(double lat, double lon, uint32_t unc_m)
{
	k_mutex_lock(&loc_lock, K_FOREVER);
	have_last_coords = true;
	last_lat = lat;
	last_lon = lon;
	last_unc_m = (unc_m > 0) ? unc_m : 1;
	k_mutex_unlock(&loc_lock);
}
```

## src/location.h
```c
/*
 * SPDX-License-Identifier: Apache-2.0
 *
 * Minimal GNSS location feature for the OSCORE nRF9151 sample.
 *
 * Framework-free take on the Asset-Tracker-Template location module: it drives
 * the nRF Connect SDK Location library (modem/location.h) with a GNSS-only
 * method and surfaces two things to the plain main() loop:
 *
 *   1. A-GNSS assistance requests raised by the modem (LOCATION_EVT_GNSS_-
 *      ASSISTANCE_REQUEST). The event handler runs on the Location library
 *      workqueue, but the assistance fetch is an OSCORE/CoAP round-trip that
 *      must be serialized with telemetry on the single cloud socket, so the
 *      request is handed to main() which performs the fetch when connected.
 *
 *   2. Completed GNSS fixes, so main() can fold them into a telemetry uplink.
 *
 * Repeat-request handling: because the server returns only a subset of the
 * constellation (pruned / capped), the GNSS core keeps re-raising the
 * assistance request for satellites it can see but was not given. We fetch at
 * most once per search; further requests in the same search are ignored and the
 * modem proceeds to a fix with the data it has (assistance is optional).
 */

#ifndef APP_LOCATION_H_
#define APP_LOCATION_H_

#include <stdbool.h>
#include <stdint.h>
#include <nrf_modem_gnss.h>

#ifdef __cplusplus
extern "C" {
#endif

/* A completed GNSS fix, ready to be folded into telemetry (agnss-schema.md 2.1). */
struct app_fix {
	double lat;         /* degrees */
	double lon;         /* degrees */
	double accuracy_m;  /* horizontal accuracy, metres */
	double alt_m;       /* altitude, metres (valid only if has_alt) */
	bool has_alt;
	uint32_t ttff_ms;   /* GNSS execution time, ms */
	int64_t timestamp;  /* unix seconds, or 0 if wall clock unknown */
};

/* Initialise the Location library and this module. Call once after the modem
 * library is up (network_init has returned). Returns 0 or a negative errno. */
int app_location_init(void);

/* Which assistance source feeds a GNSS search. The mode decides how the modem's
 * assistance-need event is served: over the network (A-GNSS), from the stored
 * predicted windows (P-GPS), or not at all. */
enum app_assist {
	/* Live A-GNSS fetch, look-ahead 0: only satellites visible now, capped to
	 * CONFIG_APP_AGNSS_SINGLE_SHOT_MAX_SV. Smallest payload per fix. */
	APP_ASSIST_AGNSS_SINGLE,
	/* Live A-GNSS fetch with the full 2 h look-ahead window. */
	APP_ASSIST_AGNSS_WINDOW,
	/* Inject the stored predicted window covering now; never goes online. */
	APP_ASSIST_PGPS,
	/* Serve nothing: the modem fixes on whatever it can decode from the sky.
	 * The control case for assistance comparisons. */
	APP_ASSIST_NONE,
};

/* Human-readable name of an assistance mode, for logs and shell output. */
const char *app_assist_name(enum app_assist mode);

/* Trigger a one-shot GNSS search served by the given assistance mode. all
 * requests the full constellation for the fetch (server skips SV pruning),
 * trading payload size for coverage; it is only meaningful for the A-GNSS modes.
 * Returns 0 or a negative errno. */
int app_location_request_assist(enum app_assist mode, bool all);

/* True while a GNSS search started here is still running. */
bool app_location_search_active(void);

/* Convenience wrapper: APP_ASSIST_AGNSS_SINGLE / APP_ASSIST_AGNSS_WINDOW. */
int app_location_request(bool single_shot, bool all);

/* Convenience wrapper: APP_ASSIST_PGPS. */
int app_location_request_pgps(void);

/* If an A-GNSS assistance request is pending (and not yet fetched for the
 * current search), copy the modem's request frame into *frame, report the
 * search's single_shot mode in *single_shot and its all (unpruned) mode in *all,
 * and return true. Any of frame/single_shot/all may be NULL. The pending flag is
 * cleared; call app_location_agnss_mark_fetched() after a successful fetch so
 * repeat requests in the same search are suppressed. */
bool app_location_agnss_pending(struct nrf_modem_gnss_agnss_data_frame *frame,
				bool *single_shot, bool *all);

/* If the current search was started with app_location_request_pgps() and the
 * modem has raised an assistance-need not yet serviced this search, copy the
 * request frame into *frame (may be NULL) and return true, clearing the pending
 * flag. Call app_location_agnss_mark_fetched() after injecting so repeat
 * requests in this search are suppressed. */
bool app_location_pgps_pending(struct nrf_modem_gnss_agnss_data_frame *frame);

/* Mark that assistance was fetched (A-GNSS) or injected (P-GPS) for the current
 * search, so subsequent LOCATION_EVT_GNSS_ASSISTANCE_REQUEST events in this
 * search are ignored. */
void app_location_agnss_mark_fetched(void);

/* If a new GNSS fix is ready, copy it into *fix and return true (clearing it). */
bool app_location_get_fix(struct app_fix *fix);

/* Number of fixes stored since boot. Lets a caller decide whether a search it
 * started produced a fix without consuming the pending one (which belongs to
 * the telemetry path, and which is not consumed at all while the link is down). */
uint32_t app_location_fix_count(void);

/* Last known GNSS coordinates, for use as an A-GNSS position hint. Returns true
 * if a fix has ever been obtained this power cycle. */
bool app_location_last_coords(double *lat, double *lon, uint32_t *unc_m);

/* Seed the last-known GNSS coordinates manually (degrees, uncertainty in metres),
 * as if a fix had been obtained. Lets a device with no fix this power cycle still
 * provide a coarse reference position for the A-GNSS / P-GPS LOCATION assistance
 * and for server-side per-window pruning. unc_m is clamped to a minimum of 1 m. */
void app_location_set_last_coords(double lat, double lon, uint32_t unc_m);

#ifdef __cplusplus
}
#endif

#endif /* APP_LOCATION_H_ */
```

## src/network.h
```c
/*
 * SPDX-License-Identifier: Apache-2.0
 *
 * Lightweight LTE link module for the OSCORE nRF9151 sample.
 *
 * This is a framework-free take on the Asset-Tracker-Template network module:
 * it owns the modem library and LTE Link Control, tracks the link state from
 * the modem's default-PDN events (so "connected" means an IP bearer is actually
 * usable, not merely that the modem registered), forwards the interesting
 * lte_lc events to a single application callback, and provides an escalating
 * recovery ladder. Unlike ATT there is no zbus / SMF / dedicated thread: events
 * arrive on the lte_lc workqueue and the plain main() loop drives connect/send
 * by polling network_is_connected() / blocking on network_wait_connected().
 */

#ifndef NETWORK_H_
#define NETWORK_H_

#include <zephyr/kernel.h>
#include <modem/lte_lc.h>

#ifdef __cplusplus
extern "C" {
#endif

/* Events delivered to the application callback. The link-state transitions
 * (CONNECTED/DISCONNECTED) are also reflected by network_is_connected() and
 * network_wait_connected(); the rest are informational. */
enum network_event {
	/* The default PDN is active: an IP bearer is available. */
	NETWORK_EVENT_CONNECTED,

	/* The default PDN went down (deactivated, suspended or detached), or the
	 * modem left the network. The transport should stop until reconnected. */
	NETWORK_EVENT_DISCONNECTED,

	/* The modem reported a SIM error (LTE_LC_NW_REG_UICC_FAIL). */
	NETWORK_EVENT_UICC_FAILURE,

	/* A network attach request was rejected (not registered). */
	NETWORK_EVENT_ATTACH_REJECTED,

	/* The modem detected an attach reset loop and will back off for ~30 min. */
	NETWORK_EVENT_MODEM_RESET_LOOP,

	/* A light (cell-history-based) network search finished without success;
	 * the modem continues with a full search unless stopped. */
	NETWORK_EVENT_LIGHT_SEARCH_DONE,

	/* A full network search finished without finding a suitable cell. */
	NETWORK_EVENT_SEARCH_DONE,

	/* Negotiated PSM parameters changed; see evt->psm_cfg. */
	NETWORK_EVENT_PSM_UPDATE,

	/* Negotiated eDRX parameters changed; see evt->edrx_cfg. */
	NETWORK_EVENT_EDRX_UPDATE,
};

struct network_evt {
	enum network_event type;
	union {
		/* Valid for NETWORK_EVENT_PSM_UPDATE. */
		IF_ENABLED(CONFIG_LTE_LC_PSM_MODULE, (struct lte_lc_psm_cfg psm_cfg));

		/* Valid for NETWORK_EVENT_EDRX_UPDATE. */
		IF_ENABLED(CONFIG_LTE_LC_EDRX_MODULE, (struct lte_lc_edrx_cfg edrx_cfg));
	};
};

/* Application event callback. Invoked from the lte_lc workqueue context, so
 * keep it short and non-blocking. May be NULL if the app only cares about the
 * link state via network_is_connected() / network_wait_connected(). */
typedef void (*network_evt_handler_t)(const struct network_evt *evt, void *user);

/* Initialise the modem library and LTE Link Control, register the event
 * handler, enable default-PDN / modem event notifications and start an
 * asynchronous network attach. Returns 0 on success or a negative errno.
 * The link comes up asynchronously; wait for it with network_wait_connected(). */
int network_init(network_evt_handler_t handler, void *user);

/* True while the default PDN is active (IP bearer usable). Lock-free snapshot
 * intended for the "is it worth trying?" checks in the main loop. */
bool network_is_connected(void);

/* Block until the link is connected, or until the timeout elapses.
 * Returns true if the link is up on return. */
bool network_wait_connected(k_timeout_t timeout);

/* Serving-cell snapshot, used as a coarse position hint for A-GNSS pruning when
 * the device has no recent GNSS fix. Populated from LTE_LC_EVT_CELL_UPDATE. */
struct network_cell {
	uint32_t id;   /* E-UTRAN cell id (0 ⇒ unknown) */
	uint32_t tac;  /* tracking area code */
	int mcc;       /* mobile country code */
	int mnc;       /* mobile network code */
	int16_t rsrp;  /* serving RSRP, dBm (0 ⇒ absent) */
	uint32_t ta;   /* timing advance (0 ⇒ absent) */
	bool valid;    /* true once a cell update with a real id has arrived */
};

/* Copy the latest serving-cell snapshot into out. Returns true if a valid cell
 * is known. Safe to call from the main loop. */
bool network_serving_cell(struct network_cell *out);

/* Escalating recovery ladder, keyed on the number of consecutive failures:
 *   - few failures: wait for the modem to re-attach on its own;
 *   - more failures: force an offline/normal re-attach;
 *   - persistent failures: shut down and reinitialise the modem library.
 * After acting it waits (bounded) for the link to return so the caller does
 * not spin.
 *
 * The caller MUST close any open transport (e.g. oscore_cloud_disconnect())
 * before calling this: a full modem-library reinit requires all sockets to be
 * closed. */
void network_recover(unsigned int failures);

#ifdef __cplusplus
}
#endif

#endif /* NETWORK_H_ */
```
